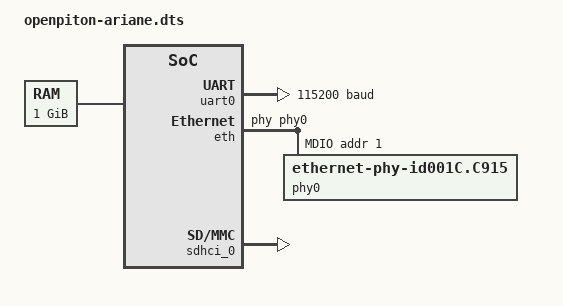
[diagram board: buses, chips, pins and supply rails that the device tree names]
// DTS generated with gen_riscv_dts(...)
// OpenPiton + Ariane framework
// Date: Mar 13 2021 13:41:04

/dts-v1/;

/ {
    #address-cells = <2>;
    #size-cells = <2>;
    u-boot,dm-pre-reloc;
    compatible = "openpiton,ariane";

    chosen {
       u-boot,dm-pre-reloc;
       bootargs = "debug loglevel=9";
       stdout-path = "uart0:115200";
    };

    aliases {
        u-boot,dm-pre-reloc;
        cpu0 = &CPU0;
        console = &uart0;
        serial0 = &uart0;
    };

    cpus {
        #address-cells = <1>;
        #size-cells = <0>;
        u-boot,dm-pre-reloc;
        timebase-frequency = <520835>;
    
        CPU0: cpu@0 {
            clock-frequency = <66667000>;
            u-boot,dm-pre-reloc;
            device_type = "cpu";
            reg = <0>;
            status = "okay";
            compatible = "eth, ariane", "riscv";
            riscv,isa = "rv64imafdc";
            mmu-type = "riscv,sv39";
            tlb-split;
            // HLIC - hart local interrupt controller
            CPU0_intc: interrupt-controller {
                #interrupt-cells = <1>;
                interrupt-controller;
                compatible = "riscv,cpu-intc";
            };
        };
        
        CPU1: cpu@1 {
            clock-frequency = <66667000>;
            u-boot,dm-pre-reloc;
            device_type = "cpu";
            reg = <1>;
            status = "okay";
            compatible = "eth, ariane", "riscv";
            riscv,isa = "rv64imafdc";
            mmu-type = "riscv,sv39";
            tlb-split;
            // HLIC - hart local interrupt controller
            CPU1_intc: interrupt-controller {
                #interrupt-cells = <1>;
                interrupt-controller;
                compatible = "riscv,cpu-intc";
            };
        };
        
    };
    
    memory@80000000 {
        u-boot,dm-pre-reloc;
        device_type = "memory";
        reg = < 0x00000000 0x80000000 0x00000000 0x40000000 >;
    };
            
        uart0: uart@fff0c2c000 {
            u-boot,dm-pre-reloc;
            compatible = "ns16550";
            reg = < 0x000000ff 0xf0c2c000 0x00000000 0x000d4000 >;
            clock-frequency = <66667000>;
            current-speed = <115200>;
            interrupt-parent = <&PLIC0>;
            interrupts = <1>;
            reg-shift = <0>; // regs are spaced on 8 bit boundary (modified from Xilinx UART16550 to be ns16550 compatible)
        };
            
        eth: ethernet@fff0d00000 {
            compatible = "xlnx,xps-ethernetlite-1.00.a";
            device_type = "network";
            reg = < 0x000000ff 0xf0d00000 0x00000000 0x00100000 >;
            interrupt-parent = <&PLIC0>;
            interrupts = <2>;
            local-mac-address = [ 00 18 3E 02 E3 E5 ];
            phy-handle = <&phy0>;
            xlnx,duplex = <0x1>;
            xlnx,include-global-buffers = <0x1>;
            xlnx,include-internal-loopback = <0x0>;
            xlnx,include-mdio = <0x1>;
            xlnx,rx-ping-pong = <0x1>;
            xlnx,s-axi-id-width = <0x1>;
            xlnx,tx-ping-pong = <0x1>;
            xlnx,use-internal = <0x0>;
            axi_ethernetlite_0_mdio: mdio {
                #address-cells = <1>;
                #size-cells = <0>;
                phy0: phy@1 {
                    compatible = "ethernet-phy-id001C.C915";
                    device_type = "ethernet-phy";
                    reg = <1>;
                };
            };
        };
            
        debug-controller@fff1000000 {
            compatible = "riscv,debug-013";
            interrupts-extended = <&CPU0_intc 65535 &CPU1_intc 65535 >;
            reg = < 0x000000ff 0xf1000000 0x00000000 0x00001000 >;
            reg-names = "control";
        };
            
        sdhci_0: sdhci@0xf000000000 {
            u-boot,dm-pre-reloc;
            status = "okay";
            compatible = "ariane,piton-mmc";
            reg = < 0x000000f0 0x00000000 0x00000000 0x00300000 >;
        };
        clint@fff1020000 {
            u-boot,dm-pre-reloc;
            compatible = "riscv,clint0";
            interrupts-extended = <&CPU0_intc 3 &CPU0_intc 7 &CPU1_intc 3 &CPU1_intc 7 >;
            reg = < 0x000000ff 0xf1020000 0x00000000 0x000c0000 >;
            reg-names = "control";
        };
            
        PLIC0: plic@fff1100000 {
            u-boot,dm-pre-reloc;
            #address-cells = <0>;
            #interrupt-cells = <1>;
            compatible = "riscv,plic0";
            interrupt-controller;
            interrupts-extended = <&CPU0_intc 11 &CPU0_intc 9 &CPU1_intc 11 &CPU1_intc 9 >;
            reg = < 0x000000ff 0xf1100000 0x00000000 0x04000000 >;
            riscv,max-priority = <7>;
            riscv,ndev = <2>;
        };
            
};
    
